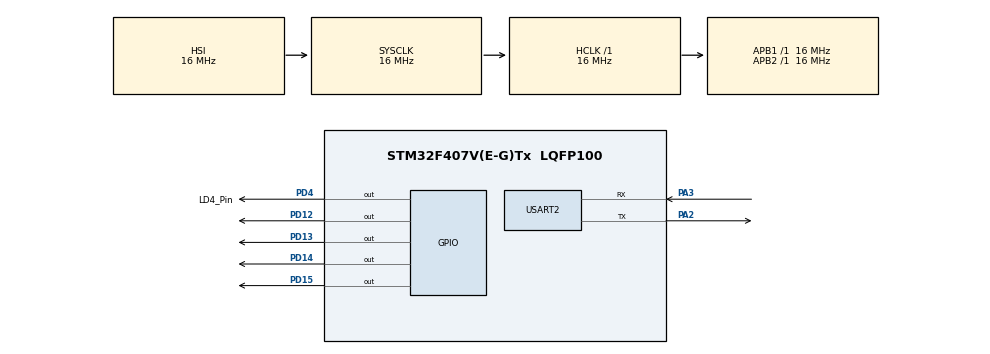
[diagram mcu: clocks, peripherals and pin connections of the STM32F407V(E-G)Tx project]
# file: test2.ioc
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Mcu.Family=STM32F4
Mcu.Name=STM32F407V(E-G)Tx
Mcu.Package=LQFP100
NVIC.PriorityGroup=NVIC_PRIORITYGROUP_4
NVIC.USART2_IRQn=true\:0\:0\:false\:false\:true\:true\:true
PA13.Mode=Serial_Wire
PA13.Signal=SYS_JTMS-SWDIO
PA14.Mode=Serial_Wire
PA14.Signal=SYS_JTCK-SWCLK
PA2.Mode=Asynchronous
PA2.Signal=USART2_TX
PA3.Mode=Asynchronous
PA3.Signal=USART2_RX
PD12.Signal=GPIO_Output
PD13.Signal=GPIO_Output
PD14.Signal=GPIO_Output
PD15.Signal=GPIO_Output
PD4.GPIO_Label=LD4_Pin
PD4.Signal=GPIO_Output
ProjectManager.HeapSize=0x200
ProjectManager.StackSize=0x400
ProjectManager.TargetToolchain=Makefile
RCC.48MHZClocksFreq_Value=12800000
RCC.AHBFreq_Value=16000000
RCC.APB1Freq_Value=16000000
RCC.APB1TimFreq_Value=16000000
RCC.APB2Freq_Value=16000000
RCC.APB2TimFreq_Value=16000000
RCC.CortexFreq_Value=16000000
RCC.HCLKFreq_Value=16000000
RCC.HSE_VALUE=8000000
RCC.HSI_VALUE=16000000
RCC.PLLM=36
RCC.PLLN=144
RCC.PLLQ=5
RCC.SYSCLKFreq_VALUE=16000000
RCC.VCOOutputFreq_Value=64000000
USART2.VirtualMode=VM_ASYNC
board=custom

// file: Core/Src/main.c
/* USER CODE BEGIN Header */
/**
  ******************************************************************************
  * @file           : main.c
  * @brief          : Main program body
  ******************************************************************************
  * @attention
  *
  * <h2><center>&copy; Copyright (c) 2021 STMicroelectronics.
  * All rights reserved.</center></h2>
  *
  * This software component is licensed by ST under BSD 3-Clause license,
  * the "License"; You may not use this file except in compliance with the
  * License. You may obtain a copy of the License at:
  *                        opensource.org/licenses/BSD-3-Clause
  *
  ******************************************************************************
  */
/* USER CODE END Header */
#include "main.h"
#include "usart.h"
#include "gpio.h"
#include "string.h"

void SystemClock_Config(void);

int main(void)
{

  /* MCU Configuration--------------------------------------------------------*/

  /* Reset of all peripherals, Initializes the Flash interface and the Systick. */
  HAL_Init();

  /* Configure the system clock */
  SystemClock_Config();

  /* Initialize all configured peripherals */
  MX_GPIO_Init();
  MX_USART2_UART_Init();

  /* Infinite loop */
  /* USER CODE BEGIN WHILE */
  char *message = "HelloWorld!\n";
  while (1)
  {
    /* USER CODE END WHILE */
    HAL_GPIO_TogglePin(GPIOD, GPIO_PIN_15);
    // HAL_Delay(100);
    HAL_GPIO_TogglePin(GPIOD, GPIO_PIN_14);
    // HAL_Delay(100);
    HAL_GPIO_TogglePin(GPIOD, GPIO_PIN_13);
    HAL_Delay(50);
    HAL_UART_Transmit(&huart2, (uint8_t *)message, strlen(message), 0xffff);
    HAL_Delay(1000);
    // CDC_Transmit_FS(buffer, sizeof(buffer));
    // HAL_Delay(1000);
  }
}

void SystemClock_Config(void)
{
  RCC_OscInitTypeDef RCC_OscInitStruct = {0};
  RCC_ClkInitTypeDef RCC_ClkInitStruct = {0};

  /** Configure the main internal regulator output voltage
  */
  __HAL_RCC_PWR_CLK_ENABLE();
  __HAL_PWR_VOLTAGESCALING_CONFIG(PWR_REGULATOR_VOLTAGE_SCALE1);
  /** Initializes the RCC Oscillators according to the specified parameters
  * in the RCC_OscInitTypeDef structure.
  */
  RCC_OscInitStruct.OscillatorType = RCC_OSCILLATORTYPE_HSI;
  RCC_OscInitStruct.HSIState = RCC_HSI_ON;
  RCC_OscInitStruct.HSICalibrationValue = RCC_HSICALIBRATION_DEFAULT;
  RCC_OscInitStruct.PLL.PLLState = RCC_PLL_NONE;
  if (HAL_RCC_OscConfig(&RCC_OscInitStruct) != HAL_OK)
  {
    Error_Handler();
  }
  /** Initializes the CPU, AHB and APB buses clocks
  */
  RCC_ClkInitStruct.ClockType = RCC_CLOCKTYPE_HCLK|RCC_CLOCKTYPE_SYSCLK
                              |RCC_CLOCKTYPE_PCLK1|RCC_CLOCKTYPE_PCLK2;
  RCC_ClkInitStruct.SYSCLKSource = RCC_SYSCLKSOURCE_HSI;
  RCC_ClkInitStruct.AHBCLKDivider = RCC_SYSCLK_DIV1;
  RCC_ClkInitStruct.APB1CLKDivider = RCC_HCLK_DIV1;
  RCC_ClkInitStruct.APB2CLKDivider = RCC_HCLK_DIV1;

  if (HAL_RCC_ClockConfig(&RCC_ClkInitStruct, FLASH_LATENCY_0) != HAL_OK)
  {
    Error_Handler();
  }
}

void Error_Handler(void)
{
  __disable_irq();
  while (1)
  {
  }
}

/************************ (C) COPYRIGHT STMicroelectronics *****END OF FILE****/
